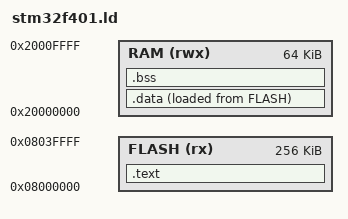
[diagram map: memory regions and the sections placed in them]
ENTRY(_start)

MEMORY
{
    FLASH (rx)  : ORIGIN = 0x08000000, LENGTH = 256K
    RAM   (rwx) : ORIGIN = 0x20000000, LENGTH = 64K
}

SECTIONS
{
    .text : {
        KEEP(*(.text._start)) /* Точка входа в самом начале Flash */
        *(.text*)
        *(.rodata*)
    } > FLASH

    .data : {
        *(.data*)
    } > RAM AT > FLASH

    .bss : {
        *(.bss*)
    } > RAM
}
